AUTOSAR XML (schema 4-2-2)
package /STELLANTIS/EPT/COMSWCs
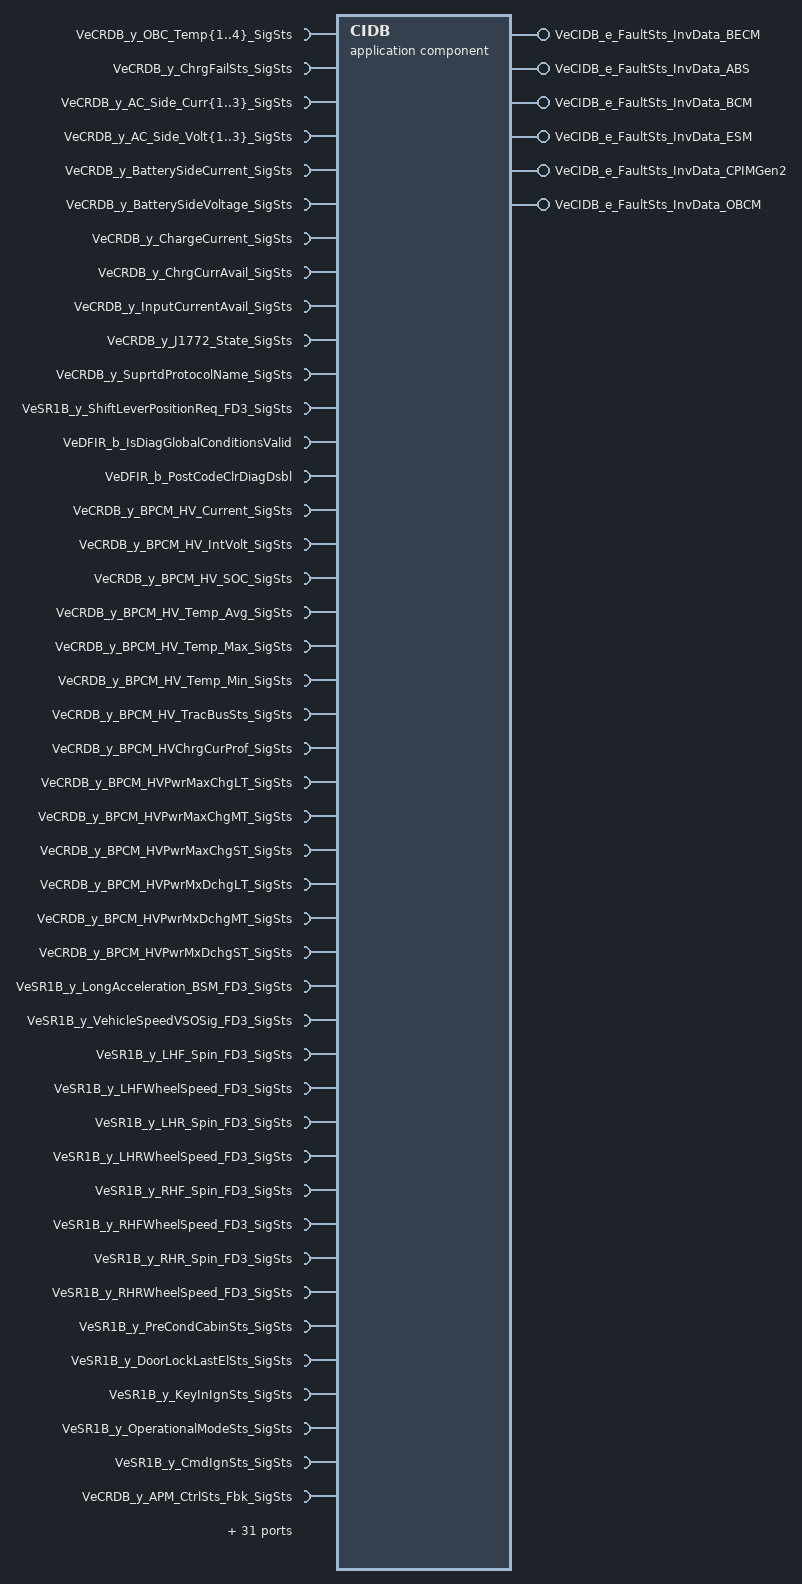
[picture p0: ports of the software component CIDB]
  application sw component type CIDB
    86 x require port:
      VeCRDB_y_OBC_Temp{1..4}_SigSts: variation-point={short-label=vpVeCRDB_y_OBC_Temp{1..4}_SigSts, sw-syscond=1}, nonqueued-receiver-com-spec{data-element=Value, init-value=0}, required-interface=VeCRDB_y_OBC_Temp{1..4}_SigSts
      VeCRDB_y_ChrgFailSts_SigSts: variation-point={short-label=vpVeCRDB_y_ChrgFailSts_SigSts, sw-syscond=1}, nonqueued-receiver-com-spec{data-element=Value, init-value=0}, required-interface=VeCRDB_y_ChrgFailSts_SigSts
      VeCRDB_y_AC_Side_Curr{1..3}_SigSts: variation-point={short-label=vpVeCRDB_y_AC_Side_Curr{1..3}_SigSts, sw-syscond=1}, nonqueued-receiver-com-spec{data-element=Value, init-value=0}, required-interface=VeCRDB_y_AC_Side_Curr{1..3}_SigSts
      VeCRDB_y_AC_Side_Volt{1..3}_SigSts: variation-point={short-label=vpVeCRDB_y_AC_Side_Volt{1..3}_SigSts, sw-syscond=1}, nonqueued-receiver-com-spec{data-element=Value, init-value=0}, required-interface=VeCRDB_y_AC_Side_Volt{1..3}_SigSts
      VeCRDB_y_BatterySideCurrent_SigSts: variation-point={short-label=vpVeCRDB_y_BatterySideCurrent_SigSts, sw-syscond=1}, nonqueued-receiver-com-spec{data-element=Value, init-value=0}, required-interface=VeCRDB_y_BatterySideCurrent_SigSts
      VeCRDB_y_BatterySideVoltage_SigSts: variation-point={short-label=vpVeCRDB_y_BatterySideVoltage_SigSts, sw-syscond=1}, nonqueued-receiver-com-spec{data-element=Value, init-value=0}, required-interface=VeCRDB_y_BatterySideVoltage_SigSts
      VeCRDB_y_ChargeCurrent_SigSts: variation-point={short-label=vpVeCRDB_y_ChargeCurrent_SigSts, sw-syscond=1}, nonqueued-receiver-com-spec{data-element=Value, init-value=0}, required-interface=VeCRDB_y_ChargeCurrent_SigSts
      VeCRDB_y_ChrgCurrAvail_SigSts: variation-point={short-label=vpVeCRDB_y_ChrgCurrAvail_SigSts, sw-syscond=1}, nonqueued-receiver-com-spec{data-element=Value, init-value=0}, required-interface=VeCRDB_y_ChrgCurrAvail_SigSts
      VeCRDB_y_InputCurrentAvail_SigSts: variation-point={short-label=vpVeCRDB_y_InputCurrentAvail_SigSts, sw-syscond=1}, nonqueued-receiver-com-spec{data-element=Value, init-value=0}, required-interface=VeCRDB_y_InputCurrentAvail_SigSts
      VeCRDB_y_J1772_State_SigSts: variation-point={short-label=vpVeCRDB_y_J1772_State_SigSts, sw-syscond=1}, nonqueued-receiver-com-spec{data-element=Value, init-value=0}, required-interface=VeCRDB_y_J1772_State_SigSts
      VeCRDB_y_SuprtdProtocolName_SigSts: variation-point={short-label=vpVeCRDB_y_SuprtdProtocolName_SigSts, sw-syscond=1}, nonqueued-receiver-com-spec{data-element=Value, init-value=0}, required-interface=VeCRDB_y_SuprtdProtocolName_SigSts
      VeSR1B_y_ShiftLeverPositionReq_FD3_SigSts: variation-point={short-label=vpVeSR1B_y_ShiftLeverPositionReq_FD3_SigSts, sw-syscond=1}, nonqueued-receiver-com-spec{data-element=Value, init-value=0}, required-interface=VeSR1B_y_ShiftLeverPositionReq_FD3_SigSts
      VeDFIR_b_IsDiagGlobalConditionsValid: nonqueued-receiver-com-spec{data-element=Value, init-value=0}, required-interface=VeDFIR_b_IsDiagGlobalConditionsValid
      VeDFIR_b_PostCodeClrDiagDsbl: nonqueued-receiver-com-spec{data-element=Value, init-value=0}, required-interface=VeDFIR_b_PostCodeClrDiagDsbl
      VeCRDB_y_BPCM_HV_Current_SigSts: variation-point={short-label=vpVeCRDB_y_BPCM_HV_Current_SigSts, sw-syscond=1}, nonqueued-receiver-com-spec{data-element=Value, init-value=0}, required-interface=VeCRDB_y_BPCM_HV_Current_SigSts
      VeCRDB_y_BPCM_HV_IntVolt_SigSts: variation-point={short-label=vpVeCRDB_y_BPCM_HV_IntVolt_SigSts, sw-syscond=1}, nonqueued-receiver-com-spec{data-element=Value, init-value=0}, required-interface=VeCRDB_y_BPCM_HV_IntVolt_SigSts
      VeCRDB_y_BPCM_HV_SOC_SigSts: variation-point={short-label=vpVeCRDB_y_BPCM_HV_SOC_SigSts, sw-syscond=1}, nonqueued-receiver-com-spec{data-element=Value, init-value=0}, required-interface=VeCRDB_y_BPCM_HV_SOC_SigSts
      VeCRDB_y_BPCM_HV_Temp_Avg_SigSts: variation-point={short-label=vpVeCRDB_y_BPCM_HV_Temp_Avg_SigSts, sw-syscond=1}, nonqueued-receiver-com-spec{data-element=Value, init-value=0}, required-interface=VeCRDB_y_BPCM_HV_Temp_Avg_SigSts
      VeCRDB_y_BPCM_HV_Temp_Max_SigSts: variation-point={short-label=vpVeCRDB_y_BPCM_HV_Temp_Max_SigSts, sw-syscond=1}, nonqueued-receiver-com-spec{data-element=Value, init-value=0}, required-interface=VeCRDB_y_BPCM_HV_Temp_Max_SigSts
      VeCRDB_y_BPCM_HV_Temp_Min_SigSts: variation-point={short-label=vpVeCRDB_y_BPCM_HV_Temp_Min_SigSts, sw-syscond=1}, nonqueued-receiver-com-spec{data-element=Value, init-value=0}, required-interface=VeCRDB_y_BPCM_HV_Temp_Min_SigSts
      VeCRDB_y_BPCM_HV_TracBusSts_SigSts: variation-point={short-label=vpVeCRDB_y_BPCM_HV_TracBusSts_SigSts, sw-syscond=1}, nonqueued-receiver-com-spec{data-element=Value, init-value=0}, required-interface=VeCRDB_y_BPCM_HV_TracBusSts_SigSts
      VeCRDB_y_BPCM_HVChrgCurProf_SigSts: variation-point={short-label=vpVeCRDB_y_BPCM_HVChrgCurProf_SigSts, sw-syscond=1}, nonqueued-receiver-com-spec{data-element=Value, init-value=0}, required-interface=VeCRDB_y_BPCM_HVChrgCurProf_SigSts
      VeCRDB_y_BPCM_HVPwrMaxChgLT_SigSts: variation-point={short-label=vpVeCRDB_y_BPCM_HVPwrMaxChgLT_SigSts, sw-syscond=1}, nonqueued-receiver-com-spec{data-element=Value, init-value=0}, required-interface=VeCRDB_y_BPCM_HVPwrMaxChgLT_SigSts
      VeCRDB_y_BPCM_HVPwrMaxChgMT_SigSts: variation-point={short-label=vpVeCRDB_y_BPCM_HVPwrMaxChgMT_SigSts, sw-syscond=1}, nonqueued-receiver-com-spec{data-element=Value, init-value=0}, required-interface=VeCRDB_y_BPCM_HVPwrMaxChgMT_SigSts
      VeCRDB_y_BPCM_HVPwrMaxChgST_SigSts: variation-point={short-label=vpVeCRDB_y_BPCM_HVPwrMaxChgST_SigSts, sw-syscond=1}, nonqueued-receiver-com-spec{data-element=Value, init-value=0}, required-interface=VeCRDB_y_BPCM_HVPwrMaxChgST_SigSts
      VeCRDB_y_BPCM_HVPwrMxDchgLT_SigSts: variation-point={short-label=vpVeCRDB_y_BPCM_HVPwrMxDchgLT_SigSts, sw-syscond=1}, nonqueued-receiver-com-spec{data-element=Value, init-value=0}, required-interface=VeCRDB_y_BPCM_HVPwrMxDchgLT_SigSts
      VeCRDB_y_BPCM_HVPwrMxDchgMT_SigSts: variation-point={short-label=vpVeCRDB_y_BPCM_HVPwrMxDchgMT_SigSts, sw-syscond=1}, nonqueued-receiver-com-spec{data-element=Value, init-value=0}, required-interface=VeCRDB_y_BPCM_HVPwrMxDchgMT_SigSts
      VeCRDB_y_BPCM_HVPwrMxDchgST_SigSts: variation-point={short-label=vpVeCRDB_y_BPCM_HVPwrMxDchgST_SigSts, sw-syscond=1}, nonqueued-receiver-com-spec{data-element=Value, init-value=0}, required-interface=VeCRDB_y_BPCM_HVPwrMxDchgST_SigSts
      VeSR1B_y_LongAcceleration_BSM_FD3_SigSts: variation-point={short-label=vpVeSR1B_y_LongAcceleration_BSM_FD3_SigSts, sw-syscond=1}, nonqueued-receiver-com-spec{data-element=Value, init-value=0}, required-interface=VeSR1B_y_LongAcceleration_BSM_FD3_SigSts
      VeSR1B_y_VehicleSpeedVSOSig_FD3_SigSts: variation-point={short-label=vpVeSR1B_y_VehicleSpeedVSOSig_FD3_SigSts, sw-syscond=1}, nonqueued-receiver-com-spec{data-element=Value, init-value=0}, required-interface=VeSR1B_y_VehicleSpeedVSOSig_FD3_SigSts
      VeSR1B_y_LHF_Spin_FD3_SigSts: variation-point={short-label=vpVeSR1B_y_LHF_Spin_FD3_SigSts, sw-syscond=1}, nonqueued-receiver-com-spec{data-element=Value, init-value=0}, required-interface=VeSR1B_y_LHF_Spin_FD3_SigSts
      VeSR1B_y_LHFWheelSpeed_FD3_SigSts: variation-point={short-label=vpVeSR1B_y_LHFWheelSpeed_FD3_SigSts, sw-syscond=1}, nonqueued-receiver-com-spec{data-element=Value, init-value=0}, required-interface=VeSR1B_y_LHFWheelSpeed_FD3_SigSts
      VeSR1B_y_LHR_Spin_FD3_SigSts: variation-point={short-label=vpVeSR1B_y_LHR_Spin_FD3_SigSts, sw-syscond=1}, nonqueued-receiver-com-spec{data-element=Value, init-value=0}, required-interface=VeSR1B_y_LHR_Spin_FD3_SigSts
      VeSR1B_y_LHRWheelSpeed_FD3_SigSts: variation-point={short-label=vpVeSR1B_y_LHRWheelSpeed_FD3_SigSts, sw-syscond=1}, nonqueued-receiver-com-spec{data-element=Value, init-value=0}, required-interface=VeSR1B_y_LHRWheelSpeed_FD3_SigSts
      VeSR1B_y_RHF_Spin_FD3_SigSts: variation-point={short-label=vpVeSR1B_y_RHF_Spin_FD3_SigSts, sw-syscond=1}, nonqueued-receiver-com-spec{data-element=Value, init-value=0}, required-interface=VeSR1B_y_RHF_Spin_FD3_SigSts
      VeSR1B_y_RHFWheelSpeed_FD3_SigSts: variation-point={short-label=vpVeSR1B_y_RHFWheelSpeed_FD3_SigSts, sw-syscond=1}, nonqueued-receiver-com-spec{data-element=Value, init-value=0}, required-interface=VeSR1B_y_RHFWheelSpeed_FD3_SigSts
      VeSR1B_y_RHR_Spin_FD3_SigSts: variation-point={short-label=vpVeSR1B_y_RHR_Spin_FD3_SigSts, sw-syscond=1}, nonqueued-receiver-com-spec{data-element=Value, init-value=0}, required-interface=VeSR1B_y_RHR_Spin_FD3_SigSts
      VeSR1B_y_RHRWheelSpeed_FD3_SigSts: variation-point={short-label=vpVeSR1B_y_RHRWheelSpeed_FD3_SigSts, sw-syscond=1}, nonqueued-receiver-com-spec{data-element=Value, init-value=0}, required-interface=VeSR1B_y_RHRWheelSpeed_FD3_SigSts
      VeSR1B_y_PreCondCabinSts_SigSts: variation-point={short-label=vpVeSR1B_y_PreCondCabinSts_SigSts, sw-syscond=1}, nonqueued-receiver-com-spec{data-element=Value, init-value=0}, required-interface=VeSR1B_y_PreCondCabinSts_SigSts
      VeSR1B_y_DoorLockLastElSts_SigSts: variation-point={short-label=vpVeSR1B_y_DoorLockLastElSts_SigSts, sw-syscond=1}, nonqueued-receiver-com-spec{data-element=Value, init-value=0}, required-interface=VeSR1B_y_DoorLockLastElSts_SigSts
      VeSR1B_y_KeyInIgnSts_SigSts: variation-point={short-label=vpVeSR1B_y_KeyInIgnSts_SigSts, sw-syscond=1}, nonqueued-receiver-com-spec{data-element=Value, init-value=0}, required-interface=VeSR1B_y_KeyInIgnSts_SigSts
      VeSR1B_y_OperationalModeSts_SigSts: variation-point={short-label=vpVeSR1B_y_OperationalModeSts_SigSts, sw-syscond=1}, nonqueued-receiver-com-spec{data-element=Value, init-value=0}, required-interface=VeSR1B_y_OperationalModeSts_SigSts
      VeSR1B_y_CmdIgnSts_SigSts: variation-point={short-label=vpVeSR1B_y_CmdIgnSts_SigSts, sw-syscond=1}, nonqueued-receiver-com-spec{data-element=Value, init-value=0}, required-interface=VeSR1B_y_CmdIgnSts_SigSts
      VeCRDB_y_APM_CtrlSts_Fbk_SigSts: variation-point={short-label=vpVeCRDB_y_APM_CtrlSts_Fbk_SigSts, sw-syscond=1}, nonqueued-receiver-com-spec{data-element=Value, init-value=0}, required-interface=VeCRDB_y_APM_CtrlSts_Fbk_SigSts
      VeCRDB_y_APM_FailureReason_SigSts: variation-point={short-label=vpVeCRDB_y_APM_FailureReason_SigSts, sw-syscond=1}, nonqueued-receiver-com-spec{data-element=Value, init-value=0}, required-interface=VeCRDB_y_APM_FailureReason_SigSts
      VeCRDB_y_APM_FailureType_SigSts: variation-point={short-label=vpVeCRDB_y_APM_FailureType_SigSts, sw-syscond=1}, nonqueued-receiver-com-spec{data-element=Value, init-value=0}, required-interface=VeCRDB_y_APM_FailureType_SigSts
      VeCRDB_y_APM_HV_I_Fbk_SigSts: variation-point={short-label=vpVeCRDB_y_APM_HV_I_Fbk_SigSts, sw-syscond=1}, nonqueued-receiver-com-spec{data-element=Value, init-value=0}, required-interface=VeCRDB_y_APM_HV_I_Fbk_SigSts
      VeCRDB_y_APM_HV_V_Fbk_SigSts: variation-point={short-label=vpVeCRDB_y_APM_HV_V_Fbk_SigSts, sw-syscond=1}, nonqueued-receiver-com-spec{data-element=Value, init-value=0}, required-interface=VeCRDB_y_APM_HV_V_Fbk_SigSts
      VeCRDB_y_APM_IdcHvSetPFdbk_SigSts: variation-point={short-label=vpVeCRDB_y_APM_IdcHvSetPFdbk_SigSts, sw-syscond=1}, nonqueued-receiver-com-spec{data-element=Value, init-value=0}, required-interface=VeCRDB_y_APM_IdcHvSetPFdbk_SigSts
      VeCRDB_y_APM_LV_I_Fbk_SigSts: variation-point={short-label=vpVeCRDB_y_APM_LV_I_Fbk_SigSts, sw-syscond=1}, nonqueued-receiver-com-spec{data-element=Value, init-value=0}, required-interface=VeCRDB_y_APM_LV_I_Fbk_SigSts
      VeCRDB_y_APM_LV_V_Fbk_SigSts: variation-point={short-label=vpVeCRDB_y_APM_LV_V_Fbk_SigSts, sw-syscond=1}, nonqueued-receiver-com-spec{data-element=Value, init-value=0}, required-interface=VeCRDB_y_APM_LV_V_Fbk_SigSts
      VeCRDB_y_APM_PSFB_Temp2_SigSts: variation-point={short-label=vpVeCRDB_y_APM_PSFB_Temp2_SigSts, sw-syscond=1}, nonqueued-receiver-com-spec{data-element=Value, init-value=0}, required-interface=VeCRDB_y_APM_PSFB_Temp2_SigSts
      VeCRDB_y_APM_PSFB_Temp1_SigSts: variation-point={short-label=vpVeCRDB_y_APM_PSFB_Temp1_SigSts, sw-syscond=1}, nonqueued-receiver-com-spec{data-element=Value, init-value=0}, required-interface=VeCRDB_y_APM_PSFB_Temp1_SigSts
      VeSR1B_y_VehiclSpeedVSOSig_FD14_SigSts: variation-point={short-label=vpVeSR1B_y_VehiclSpeedVSOSig_FD14_SigSts, sw-syscond=1}, nonqueued-receiver-com-spec{data-element=Value, init-value=0}, required-interface=VeSR1B_y_VehiclSpeedVSOSig_FD14_SigSts
      VeCRDB_y_HVCMS_EVSEMaxCurLm_SigSts: variation-point={short-label=vpVeCRDB_y_HVCMS_EVSEMaxCurLm_SigSts, sw-syscond=1}, nonqueued-receiver-com-spec{data-element=Value, init-value=0}, required-interface=VeCRDB_y_HVCMS_EVSEMaxCurLm_SigSts
      VeCRDB_y_HVCMS_EVSEMaxVltLm_SigSts: variation-point={short-label=vpVeCRDB_y_HVCMS_EVSEMaxVltLm_SigSts, sw-syscond=1}, nonqueued-receiver-com-spec{data-element=Value, init-value=0}, required-interface=VeCRDB_y_HVCMS_EVSEMaxVltLm_SigSts
      VeCRDB_y_HVCMS_EVSEMinCurLm_SigSts: variation-point={short-label=vpVeCRDB_y_HVCMS_EVSEMinCurLm_SigSts, sw-syscond=1}, nonqueued-receiver-com-spec{data-element=Value, init-value=0}, required-interface=VeCRDB_y_HVCMS_EVSEMinCurLm_SigSts
      VeCRDB_y_HVCMS_EVSEMinVltLm_SigSts: variation-point={short-label=vpVeCRDB_y_HVCMS_EVSEMinVltLm_SigSts, sw-syscond=1}, nonqueued-receiver-com-spec{data-element=Value, init-value=0}, required-interface=VeCRDB_y_HVCMS_EVSEMinVltLm_SigSts
      VeCRDB_y_HVCMS_EVSEPrsntCur_SigSts: variation-point={short-label=vpVeCRDB_y_HVCMS_EVSEPrsntCur_SigSts, sw-syscond=1}, nonqueued-receiver-com-spec{data-element=Value, init-value=0}, required-interface=VeCRDB_y_HVCMS_EVSEPrsntCur_SigSts
      VeCRDB_y_HVCMS_EVSEPrsntVlt_SigSts: variation-point={short-label=vpVeCRDB_y_HVCMS_EVSEPrsntVlt_SigSts, sw-syscond=1}, nonqueued-receiver-com-spec{data-element=Value, init-value=0}, required-interface=VeCRDB_y_HVCMS_EVSEPrsntVlt_SigSts
      VeCRDB_y_HVCMS_ResponseCode_SigSts: variation-point={short-label=vpVeCRDB_y_HVCMS_ResponseCode_SigSts, sw-syscond=1}, nonqueued-receiver-com-spec{data-element=Value, init-value=0}, required-interface=VeCRDB_y_HVCMS_ResponseCode_SigSts
      VeLINR_b_CPIM_IND1_FailStsTO: variation-point={short-label=vpVeLINR_b_CPIM_IND1_FailStsTO, sw-syscond=1}, nonqueued-receiver-com-spec{data-element=VeLINR_b_CPIM_IND1_FailStsTO, init-value=0}, required-interface=VeLINR_b_CPIM_IND1_FailStsTO
      VeLINR_e_CPIM_IND{1..5}_Fdbk: variation-point={short-label=vpVeLINR_e_CPIM_IND{1..5}_Fdbk, sw-syscond=1}, nonqueued-receiver-com-spec{data-element=VeLINR_e_CPIM_IND{1..5}_Fdbk, handle-never-received=true, init-value=0}, required-interface=VeLINR_e_CPIM_IND{1..5}_Fdbk
      VeLINR_e_CPIM_IND_Color_Fdbk: variation-point={short-label=vpVeLINR_e_CPIM_IND_Color_Fdbk, sw-syscond=1}, nonqueued-receiver-com-spec{data-element=VeLINR_e_CPIM_IND_Color_Fdbk, handle-never-received=true, init-value=0}, required-interface=VeLINR_e_CPIM_IND_Color_Fdbk
      VeCRDB_y_BPCM_Cell_Volt_Max_SigSts: variation-point={short-label=vpVeCRDB_y_BPCM_Cell_Volt_Max_SigSts, sw-syscond=1}, nonqueued-receiver-com-spec{data-element=Value, init-value=0}, required-interface=VeCRDB_y_BPCM_Cell_Volt_Max_SigSts
      VeCRDB_y_BPCM_Cell_Volt_Min_SigSts: variation-point={short-label=vpVeCRDB_y_BPCM_Cell_Volt_Min_SigSts, sw-syscond=1}, nonqueued-receiver-com-spec{data-element=Value, init-value=0}, required-interface=VeCRDB_y_BPCM_Cell_Volt_Min_SigSts
      VeDMAB_y_StatusByte_InvData_ESM: nonqueued-receiver-com-spec{data-element=Value, init-value=0}, required-interface=VeDMAB_y_StatusByte_InvData_ESM
      VeDMAB_y_StatusByte_InvData_BECM: nonqueued-receiver-com-spec{data-element=Value, init-value=0}, required-interface=VeDMAB_y_StatusByte_InvData_BECM
      VeDMAB_y_StatusByte_InvData_ABS: nonqueued-receiver-com-spec{data-element=Value, init-value=0}, required-interface=VeDMAB_y_StatusByte_InvData_ABS
      VeDMAB_y_StatusByte_InvData_BCM: nonqueued-receiver-com-spec{data-element=Value, init-value=0}, required-interface=VeDMAB_y_StatusByte_InvData_BCM
      VeDMAB_y_StatusByte_InvData_SecurGateway: nonqueued-receiver-com-spec{data-element=Value, init-value=0}, required-interface=VeDMAB_y_StatusByte_InvData_SecurGateway
      VeDMAB_y_StatusByte_InvData_CPIMGen2: nonqueued-receiver-com-spec{data-element=Value, init-value=0}, required-interface=VeDMAB_y_StatusByte_InvData_CPIMGen2
      VeDMAB_y_StatusByte_InvData_BCCM_C: nonqueued-receiver-com-spec{data-element=Value, init-value=0}, required-interface=VeDMAB_y_StatusByte_InvData_BCCM_C
      VeDFIR_b_DsblDiagFailSafe: nonqueued-receiver-com-spec{data-element=Value, init-value=0}, required-interface=VeDFIR_b_DsblDiagFailSafe
      VeDMAB_y_StatusByte_InvData_DM_PICM: nonqueued-receiver-com-spec{data-element=Value, init-value=0}, required-interface=VeDMAB_y_StatusByte_InvData_DM_PICM
    6 x provide port, all with nonqueued-sender-com-spec{data-element=Value, init-value=CeDFIB_e_Init}:
      VeCIDB_e_FaultSts_InvData_BECM: variation-point={short-label=vpVeCIDB_e_FaultSts_InvData_BECM, sw-syscond=1}, provided-interface=VeCIDB_e_FaultSts_InvData_BECM
      VeCIDB_e_FaultSts_InvData_ABS: variation-point={short-label=vpVeCIDB_e_FaultSts_InvData_ABS, sw-syscond=1}, provided-interface=VeCIDB_e_FaultSts_InvData_ABS
      VeCIDB_e_FaultSts_InvData_BCM: variation-point={short-label=vpVeCIDB_e_FaultSts_InvData_BCM, sw-syscond=1}, provided-interface=VeCIDB_e_FaultSts_InvData_BCM
      VeCIDB_e_FaultSts_InvData_ESM: variation-point={short-label=vpVeCIDB_e_FaultSts_InvData_ESM, sw-syscond=1}, provided-interface=VeCIDB_e_FaultSts_InvData_ESM
      VeCIDB_e_FaultSts_InvData_CPIMGen2: variation-point={short-label=vpVeCIDB_e_FaultSts_InvData_CPIMGen2, sw-syscond=1}, provided-interface=VeCIDB_e_FaultSts_InvData_CPIMGen2
      VeCIDB_e_FaultSts_InvData_OBCM: variation-point={short-label=vpVeCIDB_e_FaultSts_InvData_OBCM, sw-syscond=1}, provided-interface=VeCIDB_e_FaultSts_InvData_OBCM
    behavior IB_CIDB: data-type-mapping=[msADTtoIDTMapping, ADTtoIDTMapping], handle-termination-and-restart=NO-SUPPORT
      5 x timing event:
        Event_MedTED: start-on-event=CIDB_MedTED, period=0.02
        Event_SlowTEB: start-on-event=CIDB_SlowTEB, period=0.25
        Event_MedTEH: start-on-event=CIDB_MedTEH, period=0.1
        Event_MedTEB: start-on-event=CIDB_MedTEB, period=0.01
        Event_SlowTEF: start-on-event=CIDB_SlowTEF, period=1
      init event Event_CIDB_ac_Init: start-on-event=CIDB_ac_Init
      data received event Event_CIDBDRE_CPIM_HCP_FEEDBACK: start-on-event=CIDB_CPIM_HCP_FEEDBACK_Received, data=VeLINR_b_CPIM_IND1_FailStsTO.VeLINR_b_CPIM_IND1_FailStsTO
      explicit-inter-runnable-variables:
        19 x data, all with category=VALUE, sw-calibration-access=READ-ONLY:
          VeCIDB_b_IsDiagGlobalConditionsValid_out1_IRV: type=Boolean, init-value=0
          VeCIDB_b_RstDiagCntr_out1_IRV: type=Boolean, init-value=0
          VeCIDB_b_U0422_DiagnEnbl1_IRV: type=Boolean, init-value=0, variation-point={short-label=vpVeCIDB_b_U0422_DiagnEnbl1_IRV, sw-syscond=1}
          VeCIDB_b_U049C_DiagEnbl1_IRV: type=Boolean, init-value=0, variation-point={short-label=vpVeCIDB_b_U049C_DiagEnbl1_IRV, sw-syscond=1}
          VeCIDB_e_BATTERY_HV_VLIMITS_ErrState_IRV: type=TeDFIB_e_FaultDebounceStatus, init-value=CeDFIB_e_Init, variation-point={short-label=vpVeCIDB_e_BATTERY_HV_VLIMITS_ErrState_IRV, sw-syscond=1}
          VeCIDB_b_BATTERY_HV_VLIMITS_CalDiagEnbl_IRV: type=Boolean, init-value=0, variation-point={short-label=vpVeCIDB_b_BATTERY_HV_VLIMITS_CalDiagEnbl_IRV, sw-syscond=1}
          VeCIDB_e_BCM_FD_9_ErrState_IRV: type=TeDFIB_e_FaultDebounceStatus, init-value=CeDFIB_e_Init, variation-point={short-label=vpVeCIDB_e_BCM_FD_9_ErrState_IRV, sw-syscond=1}
          VeCIDB_e_BCM_FD_10_ErrState_IRV: type=TeDFIB_e_FaultDebounceStatus, init-value=CeDFIB_e_Init, variation-point={short-label=vpVeCIDB_e_BCM_FD_10_ErrState_IRV, sw-syscond=1}
          VeCIDB_b_BCM_FD_10_CalDiagEnbl_IRV: type=Boolean, init-value=0, variation-point={short-label=vpVeCIDB_b_BCM_FD_10_CalDiagEnbl_IRV, sw-syscond=1}
          VeCIDB_e_BCM_FD_12_ErrState_IRV: type=TeDFIB_e_FaultDebounceStatus, init-value=CeDFIB_e_Init, variation-point={short-label=vpVeCIDB_e_BCM_FD_12_ErrState_IRV, sw-syscond=1}
          VeCIDB_b_BCM_FD_12_CalDiagEnbl_IRV: type=Boolean, init-value=0, variation-point={short-label=vpVeCIDB_b_BCM_FD_12_CalDiagEnbl_IRV, sw-syscond=1}
          VeCIDB_b_BCM_FD_9_CalDiagEnbl_IRV: type=Boolean, init-value=0, variation-point={short-label=vpVeCIDB_b_BCM_FD_9_CalDiagEnbl_IRV, sw-syscond=1}
          VeCIDB_b_U0412_DiagEnbl_IRV: type=Boolean, init-value=0, variation-point={short-label=vpVeCIDB_b_U0412_DiagEnbl_IRV, sw-syscond=1}
          VeCIDB_e_DUALCHARGER_THERMAL_ErrState_IRV: type=TeDFIB_e_FaultDebounceStatus, init-value=CeDFIB_e_Init, variation-point={short-label=vpVeCIDB_e_DUALCHARGER_THERMAL_ErrState_IRV, sw-syscond=1}
          VeCIDB_b_DUALCHARGER_THERMAL_CalDiagEnbl_IRV: type=Boolean, init-value=0, variation-point={short-label=vpVeCIDB_b_DUALCHARGER_THERMAL_CalDiagEnbl_IRV, sw-syscond=1}
          VeCIDB_e_HV_CHARGER2_ErrState_IRV: type=TeDFIB_e_FaultDebounceStatus, init-value=CeDFIB_e_Init, variation-point={short-label=vpVeCIDB_e_HV_CHARGER2_ErrState_IRV, sw-syscond=1}
          VeCIDB_b_HV_CHARGER2_CalDiagEnbl_IRV: type=Boolean, init-value=0, variation-point={short-label=vpVeCIDB_b_HV_CHARGER2_CalDiagEnbl_IRV, sw-syscond=1}
          VeCIDB_e_HV_CHARGER1_ErrState_IRV: type=TeDFIB_e_FaultDebounceStatus, init-value=CeDFIB_e_Init, variation-point={short-label=vpVeCIDB_e_HV_CHARGER1_ErrState_IRV, sw-syscond=1}
          VeCIDB_b_HV_CHARGER1_CalDiagEnbl_IRV: type=Boolean, init-value=0, variation-point={short-label=vpVeCIDB_b_HV_CHARGER1_CalDiagEnbl_IRV, sw-syscond=1}
      7 x runnable:
        CIDB_ac_Init
          data-send-points:
            6 x access:
              OUT_VeCIDB_e_FaultSts_InvData_CPIMGen2_Value: accessed-variable=VeCIDB_e_FaultSts_InvData_CPIMGen2.Value, variation-point={short-label=vpOUT_VeCIDB_e_FaultSts_InvData_CPIMGen2_Value, sw-syscond=1}
              OUT_VeCIDB_e_FaultSts_InvData_BECM_Value: accessed-variable=VeCIDB_e_FaultSts_InvData_BECM.Value, variation-point={short-label=vpOUT_VeCIDB_e_FaultSts_InvData_BECM_Value, sw-syscond=1}
              OUT_VeCIDB_e_FaultSts_InvData_ABS_Value: accessed-variable=VeCIDB_e_FaultSts_InvData_ABS.Value, variation-point={short-label=vpOUT_VeCIDB_e_FaultSts_InvData_ABS_Value, sw-syscond=1}
              OUT_VeCIDB_e_FaultSts_InvData_BCM_Value: accessed-variable=VeCIDB_e_FaultSts_InvData_BCM.Value, variation-point={short-label=vpOUT_VeCIDB_e_FaultSts_InvData_BCM_Value, sw-syscond=1}
              OUT_VeCIDB_e_FaultSts_InvData_ESM_Value: accessed-variable=VeCIDB_e_FaultSts_InvData_ESM.Value, variation-point={short-label=vpOUT_VeCIDB_e_FaultSts_InvData_ESM_Value, sw-syscond=1}
              OUT_VeCIDB_e_FaultSts_InvData_OBCM_Value: accessed-variable=VeCIDB_e_FaultSts_InvData_OBCM.Value, variation-point={short-label=vpOUT_VeCIDB_e_FaultSts_InvData_OBCM_Value, sw-syscond=1}
          written-local-variables:
            14 x access:
              WV_VeCIDB_b_BATTERY_HV_VLIMITS_CalDiagEnbl_IRV: accessed-variable=VeCIDB_b_BATTERY_HV_VLIMITS_CalDiagEnbl_IRV, variation-point={short-label=vpWV_VeCIDB_b_BATTERY_HV_VLIMITS_CalDiagEnbl_IRV, sw-syscond=1}
              WV_VeCIDB_e_BATTERY_HV_VLIMITS_ErrState_IRV: accessed-variable=VeCIDB_e_BATTERY_HV_VLIMITS_ErrState_IRV, variation-point={short-label=vpWV_VeCIDB_e_BATTERY_HV_VLIMITS_ErrState_IRV, sw-syscond=1}
              WV_VeCIDB_b_BCM_FD_12_CalDiagEnbl_IRV: accessed-variable=VeCIDB_b_BCM_FD_12_CalDiagEnbl_IRV, variation-point={short-label=vpWV_VeCIDB_b_BCM_FD_12_CalDiagEnbl_IRV, sw-syscond=1}
              WV_VeCIDB_b_HV_CHARGER1_CalDiagEnbl_IRV: accessed-variable=VeCIDB_b_HV_CHARGER1_CalDiagEnbl_IRV, variation-point={short-label=vpWV_VeCIDB_b_HV_CHARGER1_CalDiagEnbl_IRV, sw-syscond=1}
              WV_VeCIDB_e_BCM_FD_12_ErrState_IRV: accessed-variable=VeCIDB_e_BCM_FD_12_ErrState_IRV, variation-point={short-label=vpWV_VeCIDB_e_BCM_FD_12_ErrState_IRV, sw-syscond=1}
              WV_VeCIDB_e_HV_CHARGER1_ErrState_IRV: accessed-variable=VeCIDB_e_HV_CHARGER1_ErrState_IRV, variation-point={short-label=vpWV_VeCIDB_e_HV_CHARGER1_ErrState_IRV, sw-syscond=1}
              WV_VeCIDB_b_BCM_FD_10_CalDiagEnbl_IRV: accessed-variable=VeCIDB_b_BCM_FD_10_CalDiagEnbl_IRV, variation-point={short-label=vpWV_VeCIDB_b_BCM_FD_10_CalDiagEnbl_IRV, sw-syscond=1}
              WV_VeCIDB_b_BCM_FD_9_CalDiagEnbl_IRV: accessed-variable=VeCIDB_b_BCM_FD_9_CalDiagEnbl_IRV, variation-point={short-label=vpWV_VeCIDB_b_BCM_FD_9_CalDiagEnbl_IRV, sw-syscond=1}
              WV_VeCIDB_b_DUALCHARGER_THERMAL_CalDiagEnbl_IRV: accessed-variable=VeCIDB_b_DUALCHARGER_THERMAL_CalDiagEnbl_IRV, variation-point={short-label=vpWV_VeCIDB_b_DUALCHARGER_THERMAL_CalDiagEnbl_IRV, sw-syscond=1}
              WV_VeCIDB_b_HV_CHARGER2_CalDiagEnbl_IRV: accessed-variable=VeCIDB_b_HV_CHARGER2_CalDiagEnbl_IRV, variation-point={short-label=vpWV_VeCIDB_b_HV_CHARGER2_CalDiagEnbl_IRV, sw-syscond=1}
              WV_VeCIDB_e_BCM_FD_10_ErrState_IRV: accessed-variable=VeCIDB_e_BCM_FD_10_ErrState_IRV, variation-point={short-label=vpWV_VeCIDB_e_BCM_FD_10_ErrState_IRV, sw-syscond=1}
              WV_VeCIDB_e_BCM_FD_9_ErrState_IRV: accessed-variable=VeCIDB_e_BCM_FD_9_ErrState_IRV, variation-point={short-label=vpWV_VeCIDB_e_BCM_FD_9_ErrState_IRV, sw-syscond=1}
              WV_VeCIDB_e_DUALCHARGER_THERMAL_ErrState_IRV: accessed-variable=VeCIDB_e_DUALCHARGER_THERMAL_ErrState_IRV, variation-point={short-label=vpWV_VeCIDB_e_DUALCHARGER_THERMAL_ErrState_IRV, sw-syscond=1}
              WV_VeCIDB_e_HV_CHARGER2_ErrState_IRV: accessed-variable=VeCIDB_e_HV_CHARGER2_ErrState_IRV, variation-point={short-label=vpWV_VeCIDB_e_HV_CHARGER2_ErrState_IRV, sw-syscond=1}
        CIDB_MedTED
          data-receive-point-by-arguments:
            23 x access:
              IN_VeCRDB_y_APM_CtrlSts_Fbk_SigSts_Value: accessed-variable=VeCRDB_y_APM_CtrlSts_Fbk_SigSts.Value, variation-point={short-label=vpIN_VeCRDB_y_APM_CtrlSts_Fbk_SigSts_Value, sw-syscond=1}
              IN_VeCRDB_y_APM_FailureReason_SigSts_Value: accessed-variable=VeCRDB_y_APM_FailureReason_SigSts.Value, variation-point={short-label=vpIN_VeCRDB_y_APM_FailureReason_SigSts_Value, sw-syscond=1}
              IN_VeCRDB_y_APM_FailureType_SigSts_Value: accessed-variable=VeCRDB_y_APM_FailureType_SigSts.Value, variation-point={short-label=vpIN_VeCRDB_y_APM_FailureType_SigSts_Value, sw-syscond=1}
              IN_VeCRDB_y_APM_HV_I_Fbk_SigSts_Value: accessed-variable=VeCRDB_y_APM_HV_I_Fbk_SigSts.Value, variation-point={short-label=vpIN_VeCRDB_y_APM_HV_I_Fbk_SigSts_Value, sw-syscond=1}
              IN_VeCRDB_y_APM_HV_V_Fbk_SigSts_Value: accessed-variable=VeCRDB_y_APM_HV_V_Fbk_SigSts.Value, variation-point={short-label=vpIN_VeCRDB_y_APM_HV_V_Fbk_SigSts_Value, sw-syscond=1}
              IN_VeCRDB_y_APM_IdcHvSetPFdbk_SigSts_Value: accessed-variable=VeCRDB_y_APM_IdcHvSetPFdbk_SigSts.Value, variation-point={short-label=vpIN_VeCRDB_y_APM_IdcHvSetPFdbk_SigSts_Value, sw-syscond=1}
              IN_VeCRDB_y_APM_LV_I_Fbk_SigSts_Value: accessed-variable=VeCRDB_y_APM_LV_I_Fbk_SigSts.Value, variation-point={short-label=vpIN_VeCRDB_y_APM_LV_I_Fbk_SigSts_Value, sw-syscond=1}
              IN_VeCRDB_y_APM_LV_V_Fbk_SigSts_Value: accessed-variable=VeCRDB_y_APM_LV_V_Fbk_SigSts.Value, variation-point={short-label=vpIN_VeCRDB_y_APM_LV_V_Fbk_SigSts_Value, sw-syscond=1}
              IN_VeCRDB_y_APM_PSFB_Temp1_SigSts_Value: accessed-variable=VeCRDB_y_APM_PSFB_Temp1_SigSts.Value, variation-point={short-label=vpIN_VeCRDB_y_APM_PSFB_Temp1_SigSts_Value, sw-syscond=1}
              IN_VeCRDB_y_APM_PSFB_Temp2_SigSts_Value: accessed-variable=VeCRDB_y_APM_PSFB_Temp2_SigSts.Value, variation-point={short-label=vpIN_VeCRDB_y_APM_PSFB_Temp2_SigSts_Value, sw-syscond=1}
              IN_VeCRDB_y_BPCM_Cell_Volt_Max_SigSts_Value: accessed-variable=VeCRDB_y_BPCM_Cell_Volt_Max_SigSts.Value, variation-point={short-label=vpIN_VeCRDB_y_BPCM_Cell_Volt_Max_SigSts_Value, sw-syscond=1}
              IN_VeCRDB_y_BPCM_Cell_Volt_Min_SigSts_Value: accessed-variable=VeCRDB_y_BPCM_Cell_Volt_Min_SigSts.Value, variation-point={short-label=vpIN_VeCRDB_y_BPCM_Cell_Volt_Min_SigSts_Value, sw-syscond=1}
              IN_VeCRDB_y_HVCMS_EVSEMaxCurLm_SigSts_Value: accessed-variable=VeCRDB_y_HVCMS_EVSEMaxCurLm_SigSts.Value, variation-point={short-label=vpIN_VeCRDB_y_HVCMS_EVSEMaxCurLm_SigSts_Value, sw-syscond=1}
              IN_VeCRDB_y_HVCMS_EVSEMaxVltLm_SigSts_Value: accessed-variable=VeCRDB_y_HVCMS_EVSEMaxVltLm_SigSts.Value, variation-point={short-label=vpIN_VeCRDB_y_HVCMS_EVSEMaxVltLm_SigSts_Value, sw-syscond=1}
              IN_VeCRDB_y_HVCMS_EVSEMinCurLm_SigSts_Value: accessed-variable=VeCRDB_y_HVCMS_EVSEMinCurLm_SigSts.Value, variation-point={short-label=vpIN_VeCRDB_y_HVCMS_EVSEMinCurLm_SigSts_Value, sw-syscond=1}
              IN_VeCRDB_y_HVCMS_EVSEMinVltLm_SigSts_Value: accessed-variable=VeCRDB_y_HVCMS_EVSEMinVltLm_SigSts.Value, variation-point={short-label=vpIN_VeCRDB_y_HVCMS_EVSEMinVltLm_SigSts_Value, sw-syscond=1}
              IN_VeCRDB_y_HVCMS_EVSEPrsntCur_SigSts_Value: accessed-variable=VeCRDB_y_HVCMS_EVSEPrsntCur_SigSts.Value, variation-point={short-label=vpIN_VeCRDB_y_HVCMS_EVSEPrsntCur_SigSts_Value, sw-syscond=1}
              IN_VeCRDB_y_HVCMS_EVSEPrsntVlt_SigSts_Value: accessed-variable=VeCRDB_y_HVCMS_EVSEPrsntVlt_SigSts.Value, variation-point={short-label=vpIN_VeCRDB_y_HVCMS_EVSEPrsntVlt_SigSts_Value, sw-syscond=1}
              IN_VeCRDB_y_HVCMS_ResponseCode_SigSts_Value: accessed-variable=VeCRDB_y_HVCMS_ResponseCode_SigSts.Value, variation-point={short-label=vpIN_VeCRDB_y_HVCMS_ResponseCode_SigSts_Value, sw-syscond=1}
              IN_VeDMAB_y_StatusByte_InvData_BCCM_C_Value: accessed-variable=VeDMAB_y_StatusByte_InvData_BCCM_C.Value
              IN_VeDMAB_y_StatusByte_InvData_DM_PICM_Value: accessed-variable=VeDMAB_y_StatusByte_InvData_DM_PICM.Value
              IN_VeDMAB_y_StatusByte_InvData_ESM_Value: accessed-variable=VeDMAB_y_StatusByte_InvData_ESM.Value
              IN_VeSR1B_y_ShiftLeverPositionReq_FD3_SigSts_Value: accessed-variable=VeSR1B_y_ShiftLeverPositionReq_FD3_SigSts.Value, variation-point={short-label=vpIN_VeSR1B_y_ShiftLeverPositionReq_FD3_SigSts_Value, sw-syscond=1}
          data-send-points:
            access OUT_VeCIDB_e_FaultSts_InvData_ESM_Value: accessed-variable=VeCIDB_e_FaultSts_InvData_ESM.Value, variation-point={short-label=vpOUT_VeCIDB_e_FaultSts_InvData_ESM_Value, sw-syscond=1}
            access OUT_VeCIDB_e_FaultSts_InvData_OBCM_Value: accessed-variable=VeCIDB_e_FaultSts_InvData_OBCM.Value, variation-point={short-label=vpOUT_VeCIDB_e_FaultSts_InvData_OBCM_Value, sw-syscond=1}
          read-local-variables:
            9 x access:
              RV_VeCIDB_b_DUALCHARGER_THERMAL_CalDiagEnbl_IRV: accessed-variable=VeCIDB_b_DUALCHARGER_THERMAL_CalDiagEnbl_IRV, variation-point={short-label=vpRV_VeCIDB_b_DUALCHARGER_THERMAL_CalDiagEnbl_IRV, sw-syscond=1}
              RV_VeCIDB_b_HV_CHARGER1_CalDiagEnbl_IRV: accessed-variable=VeCIDB_b_HV_CHARGER1_CalDiagEnbl_IRV, variation-point={short-label=vpRV_VeCIDB_b_HV_CHARGER1_CalDiagEnbl_IRV, sw-syscond=1}
              RV_VeCIDB_b_HV_CHARGER2_CalDiagEnbl_IRV: accessed-variable=VeCIDB_b_HV_CHARGER2_CalDiagEnbl_IRV, variation-point={short-label=vpRV_VeCIDB_b_HV_CHARGER2_CalDiagEnbl_IRV, sw-syscond=1}
              RV_VeCIDB_b_IsDiagGlobalConditionsValid_out1_IRV: accessed-variable=VeCIDB_b_IsDiagGlobalConditionsValid_out1_IRV, variation-point={short-label=vpRV_VeCIDB_b_IsDiagGlobalConditionsValid_out1_IRV, sw-syscond=1}
              RV_VeCIDB_b_RstDiagCntr_out1_IRV: accessed-variable=VeCIDB_b_RstDiagCntr_out1_IRV, variation-point={short-label=vpRV_VeCIDB_b_RstDiagCntr_out1_IRV, sw-syscond=1}
              RV_VeCIDB_b_U0412_DiagEnbl_IRV: accessed-variable=VeCIDB_b_U0412_DiagEnbl_IRV, variation-point={short-label=vpRV_VeCIDB_b_U0412_DiagEnbl_IRV, sw-syscond=1}
              RV_VeCIDB_e_DUALCHARGER_THERMAL_ErrState_IRV: accessed-variable=VeCIDB_e_DUALCHARGER_THERMAL_ErrState_IRV, variation-point={short-label=vpRV_VeCIDB_e_DUALCHARGER_THERMAL_ErrState_IRV, sw-syscond=1}
              RV_VeCIDB_e_HV_CHARGER1_ErrState_IRV: accessed-variable=VeCIDB_e_HV_CHARGER1_ErrState_IRV, variation-point={short-label=vpRV_VeCIDB_e_HV_CHARGER1_ErrState_IRV, sw-syscond=1}
              RV_VeCIDB_e_HV_CHARGER2_ErrState_IRV: accessed-variable=VeCIDB_e_HV_CHARGER2_ErrState_IRV, variation-point={short-label=vpRV_VeCIDB_e_HV_CHARGER2_ErrState_IRV, sw-syscond=1}
          written-local-variables:
            access WV_VeCIDB_b_BATTERY_HV_VLIMITS_CalDiagEnbl_IRV: accessed-variable=VeCIDB_b_BATTERY_HV_VLIMITS_CalDiagEnbl_IRV, variation-point={short-label=vpWV_VeCIDB_b_BATTERY_HV_VLIMITS_CalDiagEnbl_IRV, sw-syscond=1}
            access WV_VeCIDB_b_U049C_DiagEnbl1_IRV: accessed-variable=VeCIDB_b_U049C_DiagEnbl1_IRV, variation-point={short-label=vpWV_VeCIDB_b_U049C_DiagEnbl1_IRV, sw-syscond=1}
            access WV_VeCIDB_e_BATTERY_HV_VLIMITS_ErrState_IRV: accessed-variable=VeCIDB_e_BATTERY_HV_VLIMITS_ErrState_IRV, variation-point={short-label=vpWV_VeCIDB_e_BATTERY_HV_VLIMITS_ErrState_IRV, sw-syscond=1}
        CIDB_SlowTEB
          data-receive-point-by-arguments:
            7 x access:
              IN_VeCRDB_y_ChrgFailSts_SigSts_Value: accessed-variable=VeCRDB_y_ChrgFailSts_SigSts.Value, variation-point={short-label=vpIN_VeCRDB_y_ChrgFailSts_SigSts_Value, sw-syscond=1}
              IN_VeCRDB_y_OBC_Temp{1..4}_SigSts_Value: accessed-variable=VeCRDB_y_OBC_Temp{1..4}_SigSts.Value, variation-point={short-label=vpIN_VeCRDB_y_OBC_Temp{1..4}_SigSts_Value, sw-syscond=1}
              IN_VeSR1B_y_CmdIgnSts_SigSts_Value: accessed-variable=VeSR1B_y_CmdIgnSts_SigSts.Value, variation-point={short-label=vpIN_VeSR1B_y_CmdIgnSts_SigSts_Value, sw-syscond=1}
              IN_VeSR1B_y_DoorLockLastElSts_SigSts_Value: accessed-variable=VeSR1B_y_DoorLockLastElSts_SigSts.Value, variation-point={short-label=vpIN_VeSR1B_y_DoorLockLastElSts_SigSts_Value, sw-syscond=1}
          read-local-variables:
            access RV_VeCIDB_b_RstDiagCntr_out1_IRV: accessed-variable=VeCIDB_b_RstDiagCntr_out1_IRV, variation-point={short-label=vpRV_VeCIDB_b_RstDiagCntr_out1_IRV, sw-syscond=1}
            access RV_VeCIDB_b_U0422_DiagnEnbl1_IRV: accessed-variable=VeCIDB_b_U0422_DiagnEnbl1_IRV, variation-point={short-label=vpRV_VeCIDB_b_U0422_DiagnEnbl1_IRV, sw-syscond=1}
            access RV_VeCIDB_b_U049C_DiagEnbl1_IRV: accessed-variable=VeCIDB_b_U049C_DiagEnbl1_IRV, variation-point={short-label=vpRV_VeCIDB_b_U049C_DiagEnbl1_IRV, sw-syscond=1}
          written-local-variables:
            8 x access:
              WV_VeCIDB_b_BCM_FD_10_CalDiagEnbl_IRV: accessed-variable=VeCIDB_b_BCM_FD_10_CalDiagEnbl_IRV, variation-point={short-label=vpWV_VeCIDB_b_BCM_FD_10_CalDiagEnbl_IRV, sw-syscond=1}
              WV_VeCIDB_b_BCM_FD_9_CalDiagEnbl_IRV: accessed-variable=VeCIDB_b_BCM_FD_9_CalDiagEnbl_IRV, variation-point={short-label=vpWV_VeCIDB_b_BCM_FD_9_CalDiagEnbl_IRV, sw-syscond=1}
              WV_VeCIDB_b_DUALCHARGER_THERMAL_CalDiagEnbl_IRV: accessed-variable=VeCIDB_b_DUALCHARGER_THERMAL_CalDiagEnbl_IRV, variation-point={short-label=vpWV_VeCIDB_b_DUALCHARGER_THERMAL_CalDiagEnbl_IRV, sw-syscond=1}
              WV_VeCIDB_b_HV_CHARGER2_CalDiagEnbl_IRV: accessed-variable=VeCIDB_b_HV_CHARGER2_CalDiagEnbl_IRV, variation-point={short-label=vpWV_VeCIDB_b_HV_CHARGER2_CalDiagEnbl_IRV, sw-syscond=1}
              WV_VeCIDB_e_BCM_FD_10_ErrState_IRV: accessed-variable=VeCIDB_e_BCM_FD_10_ErrState_IRV, variation-point={short-label=vpWV_VeCIDB_e_BCM_FD_10_ErrState_IRV, sw-syscond=1}
              WV_VeCIDB_e_BCM_FD_9_ErrState_IRV: accessed-variable=VeCIDB_e_BCM_FD_9_ErrState_IRV, variation-point={short-label=vpWV_VeCIDB_e_BCM_FD_9_ErrState_IRV, sw-syscond=1}
              WV_VeCIDB_e_DUALCHARGER_THERMAL_ErrState_IRV: accessed-variable=VeCIDB_e_DUALCHARGER_THERMAL_ErrState_IRV, variation-point={short-label=vpWV_VeCIDB_e_DUALCHARGER_THERMAL_ErrState_IRV, sw-syscond=1}
              WV_VeCIDB_e_HV_CHARGER2_ErrState_IRV: accessed-variable=VeCIDB_e_HV_CHARGER2_ErrState_IRV, variation-point={short-label=vpWV_VeCIDB_e_HV_CHARGER2_ErrState_IRV, sw-syscond=1}
        CIDB_MedTEH
          data-receive-point-by-arguments:
            14 x access:
              IN_VeCRDB_y_AC_Side_Curr{1..3}_SigSts_Value: accessed-variable=VeCRDB_y_AC_Side_Curr{1..3}_SigSts.Value, variation-point={short-label=vpIN_VeCRDB_y_AC_Side_Curr{1..3}_SigSts_Value, sw-syscond=1}
              IN_VeCRDB_y_AC_Side_Volt{1..3}_SigSts_Value: accessed-variable=VeCRDB_y_AC_Side_Volt{1..3}_SigSts.Value, variation-point={short-label=vpIN_VeCRDB_y_AC_Side_Volt{1..3}_SigSts_Value, sw-syscond=1}
              IN_VeCRDB_y_BatterySideCurrent_SigSts_Value: accessed-variable=VeCRDB_y_BatterySideCurrent_SigSts.Value, variation-point={short-label=vpIN_VeCRDB_y_BatterySideCurrent_SigSts_Value, sw-syscond=1}
              IN_VeCRDB_y_BatterySideVoltage_SigSts_Value: accessed-variable=VeCRDB_y_BatterySideVoltage_SigSts.Value, variation-point={short-label=vpIN_VeCRDB_y_BatterySideVoltage_SigSts_Value, sw-syscond=1}
              IN_VeCRDB_y_ChargeCurrent_SigSts_Value: accessed-variable=VeCRDB_y_ChargeCurrent_SigSts.Value, variation-point={short-label=vpIN_VeCRDB_y_ChargeCurrent_SigSts_Value, sw-syscond=1}
              IN_VeCRDB_y_ChrgCurrAvail_SigSts_Value: accessed-variable=VeCRDB_y_ChrgCurrAvail_SigSts.Value, variation-point={short-label=vpIN_VeCRDB_y_ChrgCurrAvail_SigSts_Value, sw-syscond=1}
              IN_VeCRDB_y_InputCurrentAvail_SigSts_Value: accessed-variable=VeCRDB_y_InputCurrentAvail_SigSts.Value, variation-point={short-label=vpIN_VeCRDB_y_InputCurrentAvail_SigSts_Value, sw-syscond=1}
              IN_VeCRDB_y_J1772_State_SigSts_Value: accessed-variable=VeCRDB_y_J1772_State_SigSts.Value, variation-point={short-label=vpIN_VeCRDB_y_J1772_State_SigSts_Value, sw-syscond=1}
              IN_VeCRDB_y_SuprtdProtocolName_SigSts_Value: accessed-variable=VeCRDB_y_SuprtdProtocolName_SigSts.Value, variation-point={short-label=vpIN_VeCRDB_y_SuprtdProtocolName_SigSts_Value, sw-syscond=1}
              IN_VeSR1B_y_PreCondCabinSts_SigSts_Value: accessed-variable=VeSR1B_y_PreCondCabinSts_SigSts.Value, variation-point={short-label=vpIN_VeSR1B_y_PreCondCabinSts_SigSts_Value, sw-syscond=1}
          read-local-variables:
            access RV_VeCIDB_b_RstDiagCntr_out1_IRV: accessed-variable=VeCIDB_b_RstDiagCntr_out1_IRV, variation-point={short-label=vpRV_VeCIDB_b_RstDiagCntr_out1_IRV, sw-syscond=1}
            access RV_VeCIDB_b_U0422_DiagnEnbl1_IRV: accessed-variable=VeCIDB_b_U0422_DiagnEnbl1_IRV, variation-point={short-label=vpRV_VeCIDB_b_U0422_DiagnEnbl1_IRV, sw-syscond=1}
            access RV_VeCIDB_b_U049C_DiagEnbl1_IRV: accessed-variable=VeCIDB_b_U049C_DiagEnbl1_IRV, variation-point={short-label=vpRV_VeCIDB_b_U049C_DiagEnbl1_IRV, sw-syscond=1}
          written-local-variables:
            4 x access:
              WV_VeCIDB_b_BCM_FD_12_CalDiagEnbl_IRV: accessed-variable=VeCIDB_b_BCM_FD_12_CalDiagEnbl_IRV, variation-point={short-label=vpWV_VeCIDB_b_BCM_FD_12_CalDiagEnbl_IRV, sw-syscond=1}
              WV_VeCIDB_b_HV_CHARGER1_CalDiagEnbl_IRV: accessed-variable=VeCIDB_b_HV_CHARGER1_CalDiagEnbl_IRV, variation-point={short-label=vpWV_VeCIDB_b_HV_CHARGER1_CalDiagEnbl_IRV, sw-syscond=1}
              WV_VeCIDB_e_BCM_FD_12_ErrState_IRV: accessed-variable=VeCIDB_e_BCM_FD_12_ErrState_IRV, variation-point={short-label=vpWV_VeCIDB_e_BCM_FD_12_ErrState_IRV, sw-syscond=1}
              WV_VeCIDB_e_HV_CHARGER1_ErrState_IRV: accessed-variable=VeCIDB_e_HV_CHARGER1_ErrState_IRV, variation-point={short-label=vpWV_VeCIDB_e_HV_CHARGER1_ErrState_IRV, sw-syscond=1}
        CIDB_MedTEB
          data-receive-point-by-arguments:
            33 x access:
              IN_VeCRDB_y_BPCM_HVChrgCurProf_SigSts_Value: accessed-variable=VeCRDB_y_BPCM_HVChrgCurProf_SigSts.Value, variation-point={short-label=vpIN_VeCRDB_y_BPCM_HVChrgCurProf_SigSts_Value, sw-syscond=1}
              IN_VeCRDB_y_BPCM_HVPwrMaxChgLT_SigSts_Value: accessed-variable=VeCRDB_y_BPCM_HVPwrMaxChgLT_SigSts.Value, variation-point={short-label=vpIN_VeCRDB_y_BPCM_HVPwrMaxChgLT_SigSts_Value, sw-syscond=1}
              IN_VeCRDB_y_BPCM_HVPwrMaxChgMT_SigSts_Value: accessed-variable=VeCRDB_y_BPCM_HVPwrMaxChgMT_SigSts.Value, variation-point={short-label=vpIN_VeCRDB_y_BPCM_HVPwrMaxChgMT_SigSts_Value, sw-syscond=1}
              IN_VeCRDB_y_BPCM_HVPwrMaxChgST_SigSts_Value: accessed-variable=VeCRDB_y_BPCM_HVPwrMaxChgST_SigSts.Value, variation-point={short-label=vpIN_VeCRDB_y_BPCM_HVPwrMaxChgST_SigSts_Value, sw-syscond=1}
              IN_VeCRDB_y_BPCM_HVPwrMxDchgLT_SigSts_Value: accessed-variable=VeCRDB_y_BPCM_HVPwrMxDchgLT_SigSts.Value, variation-point={short-label=vpIN_VeCRDB_y_BPCM_HVPwrMxDchgLT_SigSts_Value, sw-syscond=1}
              IN_VeCRDB_y_BPCM_HVPwrMxDchgMT_SigSts_Value: accessed-variable=VeCRDB_y_BPCM_HVPwrMxDchgMT_SigSts.Value, variation-point={short-label=vpIN_VeCRDB_y_BPCM_HVPwrMxDchgMT_SigSts_Value, sw-syscond=1}
              IN_VeCRDB_y_BPCM_HVPwrMxDchgST_SigSts_Value: accessed-variable=VeCRDB_y_BPCM_HVPwrMxDchgST_SigSts.Value, variation-point={short-label=vpIN_VeCRDB_y_BPCM_HVPwrMxDchgST_SigSts_Value, sw-syscond=1}
              IN_VeCRDB_y_BPCM_HV_Current_SigSts_Value: accessed-variable=VeCRDB_y_BPCM_HV_Current_SigSts.Value, variation-point={short-label=vpIN_VeCRDB_y_BPCM_HV_Current_SigSts_Value, sw-syscond=1}
              IN_VeCRDB_y_BPCM_HV_IntVolt_SigSts_Value: accessed-variable=VeCRDB_y_BPCM_HV_IntVolt_SigSts.Value, variation-point={short-label=vpIN_VeCRDB_y_BPCM_HV_IntVolt_SigSts_Value, sw-syscond=1}
              IN_VeCRDB_y_BPCM_HV_SOC_SigSts_Value: accessed-variable=VeCRDB_y_BPCM_HV_SOC_SigSts.Value, variation-point={short-label=vpIN_VeCRDB_y_BPCM_HV_SOC_SigSts_Value, sw-syscond=1}
              IN_VeCRDB_y_BPCM_HV_Temp_Avg_SigSts_Value: accessed-variable=VeCRDB_y_BPCM_HV_Temp_Avg_SigSts.Value, variation-point={short-label=vpIN_VeCRDB_y_BPCM_HV_Temp_Avg_SigSts_Value, sw-syscond=1}
              IN_VeCRDB_y_BPCM_HV_Temp_Max_SigSts_Value: accessed-variable=VeCRDB_y_BPCM_HV_Temp_Max_SigSts.Value, variation-point={short-label=vpIN_VeCRDB_y_BPCM_HV_Temp_Max_SigSts_Value, sw-syscond=1}
              IN_VeCRDB_y_BPCM_HV_Temp_Min_SigSts_Value: accessed-variable=VeCRDB_y_BPCM_HV_Temp_Min_SigSts.Value, variation-point={short-label=vpIN_VeCRDB_y_BPCM_HV_Temp_Min_SigSts_Value, sw-syscond=1}
              IN_VeCRDB_y_BPCM_HV_TracBusSts_SigSts_Value: accessed-variable=VeCRDB_y_BPCM_HV_TracBusSts_SigSts.Value, variation-point={short-label=vpIN_VeCRDB_y_BPCM_HV_TracBusSts_SigSts_Value, sw-syscond=1}
              IN_VeDFIR_b_DsblDiagFailSafe_Value: accessed-variable=VeDFIR_b_DsblDiagFailSafe.Value
              IN_VeDFIR_b_IsDiagGlobalConditionsValid_Value: accessed-variable=VeDFIR_b_IsDiagGlobalConditionsValid.Value
              IN_VeDFIR_b_PostCodeClrDiagDsbl_Value: accessed-variable=VeDFIR_b_PostCodeClrDiagDsbl.Value
              IN_VeDMAB_y_StatusByte_InvData_ABS_Value: accessed-variable=VeDMAB_y_StatusByte_InvData_ABS.Value
              IN_VeDMAB_y_StatusByte_InvData_BCM_Value: accessed-variable=VeDMAB_y_StatusByte_InvData_BCM.Value
              IN_VeDMAB_y_StatusByte_InvData_BECM_Value: accessed-variable=VeDMAB_y_StatusByte_InvData_BECM.Value
              IN_VeSR1B_y_KeyInIgnSts_SigSts_Value: accessed-variable=VeSR1B_y_KeyInIgnSts_SigSts.Value, variation-point={short-label=vpIN_VeSR1B_y_KeyInIgnSts_SigSts_Value, sw-syscond=1}
              IN_VeSR1B_y_LHFWheelSpeed_FD3_SigSts_Value: accessed-variable=VeSR1B_y_LHFWheelSpeed_FD3_SigSts.Value, variation-point={short-label=vpIN_VeSR1B_y_LHFWheelSpeed_FD3_SigSts_Value, sw-syscond=1}
              IN_VeSR1B_y_LHF_Spin_FD3_SigSts_Value: accessed-variable=VeSR1B_y_LHF_Spin_FD3_SigSts.Value, variation-point={short-label=vpIN_VeSR1B_y_LHF_Spin_FD3_SigSts_Value, sw-syscond=1}
              IN_VeSR1B_y_LHRWheelSpeed_FD3_SigSts_Value: accessed-variable=VeSR1B_y_LHRWheelSpeed_FD3_SigSts.Value, variation-point={short-label=vpIN_VeSR1B_y_LHRWheelSpeed_FD3_SigSts_Value, sw-syscond=1}
              IN_VeSR1B_y_LHR_Spin_FD3_SigSts_Value: accessed-variable=VeSR1B_y_LHR_Spin_FD3_SigSts.Value, variation-point={short-label=vpIN_VeSR1B_y_LHR_Spin_FD3_SigSts_Value, sw-syscond=1}
              IN_VeSR1B_y_LongAcceleration_BSM_FD3_SigSts_Value: accessed-variable=VeSR1B_y_LongAcceleration_BSM_FD3_SigSts.Value, variation-point={short-label=vpIN_VeSR1B_y_LongAcceleration_BSM_FD3_SigSts_Value, sw-syscond=1}
              IN_VeSR1B_y_OperationalModeSts_SigSts_Value: accessed-variable=VeSR1B_y_OperationalModeSts_SigSts.Value, variation-point={short-label=vpIN_VeSR1B_y_OperationalModeSts_SigSts_Value, sw-syscond=1}
              IN_VeSR1B_y_RHFWheelSpeed_FD3_SigSts_Value: accessed-variable=VeSR1B_y_RHFWheelSpeed_FD3_SigSts.Value, variation-point={short-label=vpIN_VeSR1B_y_RHFWheelSpeed_FD3_SigSts_Value, sw-syscond=1}
              IN_VeSR1B_y_RHF_Spin_FD3_SigSts_Value: accessed-variable=VeSR1B_y_RHF_Spin_FD3_SigSts.Value, variation-point={short-label=vpIN_VeSR1B_y_RHF_Spin_FD3_SigSts_Value, sw-syscond=1}
              IN_VeSR1B_y_RHRWheelSpeed_FD3_SigSts_Value: accessed-variable=VeSR1B_y_RHRWheelSpeed_FD3_SigSts.Value, variation-point={short-label=vpIN_VeSR1B_y_RHRWheelSpeed_FD3_SigSts_Value, sw-syscond=1}
              IN_VeSR1B_y_RHR_Spin_FD3_SigSts_Value: accessed-variable=VeSR1B_y_RHR_Spin_FD3_SigSts.Value, variation-point={short-label=vpIN_VeSR1B_y_RHR_Spin_FD3_SigSts_Value, sw-syscond=1}
              IN_VeSR1B_y_VehiclSpeedVSOSig_FD14_SigSts_Value: accessed-variable=VeSR1B_y_VehiclSpeedVSOSig_FD14_SigSts.Value, variation-point={short-label=vpIN_VeSR1B_y_VehiclSpeedVSOSig_FD14_SigSts_Value, sw-syscond=1}
              IN_VeSR1B_y_VehicleSpeedVSOSig_FD3_SigSts_Value: accessed-variable=VeSR1B_y_VehicleSpeedVSOSig_FD3_SigSts.Value, variation-point={short-label=vpIN_VeSR1B_y_VehicleSpeedVSOSig_FD3_SigSts_Value, sw-syscond=1}
          data-send-points:
            access OUT_VeCIDB_e_FaultSts_InvData_BECM_Value: accessed-variable=VeCIDB_e_FaultSts_InvData_BECM.Value, variation-point={short-label=vpOUT_VeCIDB_e_FaultSts_InvData_BECM_Value, sw-syscond=1}
            access OUT_VeCIDB_e_FaultSts_InvData_ABS_Value: accessed-variable=VeCIDB_e_FaultSts_InvData_ABS.Value, variation-point={short-label=vpOUT_VeCIDB_e_FaultSts_InvData_ABS_Value, sw-syscond=1}
            access OUT_VeCIDB_e_FaultSts_InvData_BCM_Value: accessed-variable=VeCIDB_e_FaultSts_InvData_BCM.Value, variation-point={short-label=vpOUT_VeCIDB_e_FaultSts_InvData_BCM_Value, sw-syscond=1}
          read-local-variables:
            8 x access:
              RV_VeCIDB_b_BATTERY_HV_VLIMITS_CalDiagEnbl_IRV: accessed-variable=VeCIDB_b_BATTERY_HV_VLIMITS_CalDiagEnbl_IRV, variation-point={short-label=vpRV_VeCIDB_b_BATTERY_HV_VLIMITS_CalDiagEnbl_IRV, sw-syscond=1}
              RV_VeCIDB_b_BCM_FD_10_CalDiagEnbl_IRV: accessed-variable=VeCIDB_b_BCM_FD_10_CalDiagEnbl_IRV, variation-point={short-label=vpRV_VeCIDB_b_BCM_FD_10_CalDiagEnbl_IRV, sw-syscond=1}
              RV_VeCIDB_b_BCM_FD_12_CalDiagEnbl_IRV: accessed-variable=VeCIDB_b_BCM_FD_12_CalDiagEnbl_IRV, variation-point={short-label=vpRV_VeCIDB_b_BCM_FD_12_CalDiagEnbl_IRV, sw-syscond=1}
              RV_VeCIDB_b_BCM_FD_9_CalDiagEnbl_IRV: accessed-variable=VeCIDB_b_BCM_FD_9_CalDiagEnbl_IRV, variation-point={short-label=vpRV_VeCIDB_b_BCM_FD_9_CalDiagEnbl_IRV, sw-syscond=1}
              RV_VeCIDB_e_BATTERY_HV_VLIMITS_ErrState_IRV: accessed-variable=VeCIDB_e_BATTERY_HV_VLIMITS_ErrState_IRV, variation-point={short-label=vpRV_VeCIDB_e_BATTERY_HV_VLIMITS_ErrState_IRV, sw-syscond=1}
              RV_VeCIDB_e_BCM_FD_10_ErrState_IRV: accessed-variable=VeCIDB_e_BCM_FD_10_ErrState_IRV, variation-point={short-label=vpRV_VeCIDB_e_BCM_FD_10_ErrState_IRV, sw-syscond=1}
              RV_VeCIDB_e_BCM_FD_12_ErrState_IRV: accessed-variable=VeCIDB_e_BCM_FD_12_ErrState_IRV, variation-point={short-label=vpRV_VeCIDB_e_BCM_FD_12_ErrState_IRV, sw-syscond=1}
              RV_VeCIDB_e_BCM_FD_9_ErrState_IRV: accessed-variable=VeCIDB_e_BCM_FD_9_ErrState_IRV, variation-point={short-label=vpRV_VeCIDB_e_BCM_FD_9_ErrState_IRV, sw-syscond=1}
          written-local-variables:
            4 x access:
              WV_VeCIDB_b_IsDiagGlobalConditionsValid_out1_IRV: accessed-variable=VeCIDB_b_IsDiagGlobalConditionsValid_out1_IRV
              WV_VeCIDB_b_RstDiagCntr_out1_IRV: accessed-variable=VeCIDB_b_RstDiagCntr_out1_IRV
              WV_VeCIDB_b_U0412_DiagEnbl_IRV: accessed-variable=VeCIDB_b_U0412_DiagEnbl_IRV, variation-point={short-label=vpWV_VeCIDB_b_U0412_DiagEnbl_IRV, sw-syscond=1}
              WV_VeCIDB_b_U0422_DiagnEnbl1_IRV: accessed-variable=VeCIDB_b_U0422_DiagnEnbl1_IRV, variation-point={short-label=vpWV_VeCIDB_b_U0422_DiagnEnbl1_IRV, sw-syscond=1}
        CIDB_SlowTEF
          data-receive-point-by-arguments:
            access IN_VeDMAB_y_StatusByte_InvData_SecurGateway_Value: accessed-variable=VeDMAB_y_StatusByte_InvData_SecurGateway.Value
        CIDB_CPIM_HCP_FEEDBACK_Received
          data-receive-point-by-arguments:
            8 x access:
              IN_VeDMAB_y_StatusByte_InvData_CPIMGen2_Value: accessed-variable=VeDMAB_y_StatusByte_InvData_CPIMGen2.Value
              IN_VeLINR_b_CPIM_IND1_FailStsTO_VeLINR_b_CPIM_IND1_FailStsTO: accessed-variable=VeLINR_b_CPIM_IND1_FailStsTO.VeLINR_b_CPIM_IND1_FailStsTO, variation-point={short-label=vpIN_VeLINR_b_CPIM_IND1_FailStsTO_VeLINR_b_CPIM_IND1_FailStsTO, sw-syscond=1}
              IN_VeLINR_e_CPIM_IND{1..5}_Fdbk_VeLINR_e_CPIM_IND{1..5}_Fdbk: accessed-variable=VeLINR_e_CPIM_IND{1..5}_Fdbk.VeLINR_e_CPIM_IND{1..5}_Fdbk, variation-point={short-label=vpIN_VeLINR_e_CPIM_IND{1..5}_Fdbk_VeLINR_e_CPIM_IND{1..5}_Fdbk, sw-syscond=1}
              IN_VeLINR_e_CPIM_IND_Color_Fdbk_VeLINR_e_CPIM_IND_Color_Fdbk: accessed-variable=VeLINR_e_CPIM_IND_Color_Fdbk.VeLINR_e_CPIM_IND_Color_Fdbk, variation-point={short-label=vpIN_VeLINR_e_CPIM_IND_Color_Fdbk_VeLINR_e_CPIM_IND_Color_Fdbk, sw-syscond=1}
          data-send-points:
            access OUT_VeCIDB_e_FaultSts_InvData_CPIMGen2_Value: accessed-variable=VeCIDB_e_FaultSts_InvData_CPIMGen2.Value, variation-point={short-label=vpOUT_VeCIDB_e_FaultSts_InvData_CPIMGen2_Value, sw-syscond=1}
          read-local-variables:
            access RV_VeCIDB_b_IsDiagGlobalConditionsValid_out1_IRV: accessed-variable=VeCIDB_b_IsDiagGlobalConditionsValid_out1_IRV, variation-point={short-label=vpRV_VeCIDB_b_IsDiagGlobalConditionsValid_out1_IRV, sw-syscond=1}
            access RV_VeCIDB_b_RstDiagCntr_out1_IRV: accessed-variable=VeCIDB_b_RstDiagCntr_out1_IRV, variation-point={short-label=vpRV_VeCIDB_b_RstDiagCntr_out1_IRV, sw-syscond=1}
      19 x variation point proxy, all with category=CONDITION:
        Variant_CIDB_U0404_BLUEN: condition-access=0
        Variant_CIDB_U0404_Corebev: condition-access=1
        Variant_CIDB_U0404_Pegasus: condition-access=0
        Variant_CIDB_U0412_BLUEN: condition-access=0
        Variant_CIDB_U0412_Corebev: condition-access=1
        Variant_CIDB_U0412_Pegasus: condition-access=0
        Variant_CIDB_U0415_BLUEN: condition-access=0
        Variant_CIDB_U0415_Corebev: condition-access=1
        Variant_CIDB_U0415_Pegasus: condition-access=0
        Variant_CIDB_U0422_BLUEN: condition-access=0
        Variant_CIDB_U0422_Corebev: condition-access=1
        Variant_CIDB_U0422_Pegasus: condition-access=0
        Variant_CIDB_U044A_BLUEN: condition-access=0
        Variant_CIDB_U044A_Pegasus_Corebev: condition-access=0
        Variant_CIDB_U048D_BLUEN: condition-access=0
        Variant_CIDB_U049C_Corebev: condition-access=1
        Variant_CIDB_U049C_Pegasus: condition-access=0
        Variant_CIDB_U149A_Corebev: condition-access=1
        Variant_CIDB_U149A_Pegasus: condition-access=0
